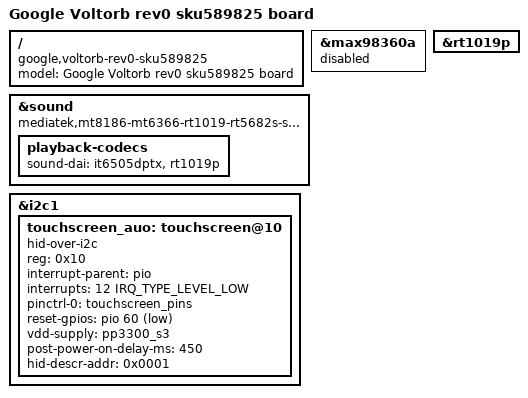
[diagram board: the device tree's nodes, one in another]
// SPDX-License-Identifier: (GPL-2.0 OR MIT)
/*
 * Copyright 2022 Google LLC
 */

/dts-v1/;
#include "mt8186-corsola-voltorb.dtsi"

/ {
	model = "Google Voltorb rev0 sku589825 board";
	compatible = "google,voltorb-rev0-sku589825", "google,voltorb",
		     "mediatek,mt8186";
};

&max98360a {
	status = "disabled";
};

&rt1019p{
	status = "okay";
};

&sound {
	compatible = "mediatek,mt8186-mt6366-rt1019-rt5682s-sound";
	playback-codecs {
		sound-dai = <&it6505dptx>,<&rt1019p>;
	};
};

&i2c1 {
	touchscreen_auo: touchscreen@10 {
		status = "okay";

		compatible = "hid-over-i2c";
		reg = <0x10>;
		interrupt-parent = <&pio>;
		interrupts = <12 IRQ_TYPE_LEVEL_LOW>;
		pinctrl-names = "default";
		pinctrl-0 = <&touchscreen_pins>;
		reset-gpios = <&pio 60 GPIO_ACTIVE_LOW>;
		vdd-supply = <&pp3300_s3>;

		post-power-on-delay-ms = <450>;
		hid-descr-addr = <0x0001>;
	};
};
